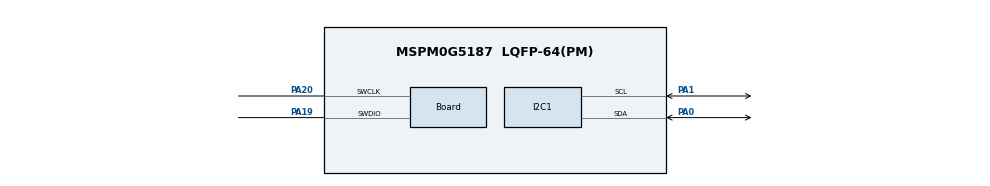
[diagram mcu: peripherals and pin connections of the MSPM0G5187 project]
//@cliArgs --device "MSPM0G518X" --part "Default" --package "LQFP-64(PM)" 
//@v2CliArgs --device "MSPM0G5187" --package "LQFP-64(PM)"
// @cliArgs --board /ti/boards/LP_MSPM0G5187 --rtos nortos

/**
 * Import the modules used in this configuration.
 */
const CRCP = scripting.addModule("/ti/driverlib/CRCP");
const I2C  = scripting.addModule("/ti/driverlib/I2C", {}, false);
const I2C1 = I2C.addInstance();

/**
 * Write custom configuration values to the imported modules.
 */
CRCP.polynomial = "16_POLYNOMIAL_CCIT_ZERO";
CRCP.seed       = 0xFFFF;

const Board                       = scripting.addModule("/ti/driverlib/Board", {}, false);
Board.peripheral.$assign          = "DEBUGSS";
Board.peripheral.swclkPin.$assign = "PA20";
Board.peripheral.swdioPin.$assign = "PA19";

I2C1.basicEnableController             = true;
I2C1.$name                             = "I2C";
I2C1.intController                     = ["ARBITRATION_LOST","NACK","RXFIFO_TRIGGER","RX_DONE","TX_DONE"];
I2C1.basicControllerStandardBusSpeed   = "Fast";
I2C1.advControllerTXFIFOTRIG           = "3_4_EMPTY";
I2C1.peripheral.$assign                = "UC0";
I2C1.peripheral.sdaPin.$assign         = "PA0";
I2C1.peripheral.sclPin.$assign         = "PA1";
I2C1.sdaPinConfig.enableConfig         = true;
I2C1.sclPinConfig.enableConfig         = true;

const SYSCTL                 = scripting.addModule("/ti/driverlib/SYSCTL", {}, false);
SYSCTL.forceDefaultClkConfig = true;
SYSCTL.clockTreeEn           = true;

const ProjectConfig              = scripting.addModule("/ti/project_config/ProjectConfig", {}, false);
ProjectConfig.migrationCondition = true;
